# f29h85x_hsm_dcc0_regs register map
Vendor: Texas Instruments
Peripheral module from a debugger description file (folder HSM).
Registers are 32-bit, read-write, no defined reset value unless marked. A register's access mark holds for its fields unless they carry their own. Offsets are as the file gives them; lines under a group give offsets from that group; [hi:lo] are bit positions; {n}, {i} and the like mark numbered series; 'fields as' and 'values as' point back to an identical list; <NAME> marks a mode.

## HSM_DCC0 — HSM DCC0 Registers
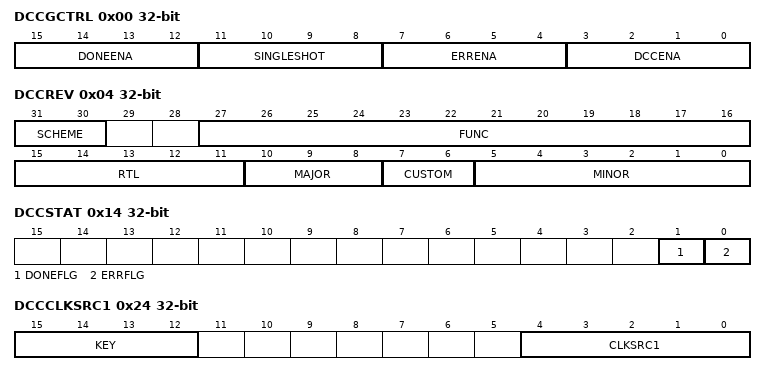
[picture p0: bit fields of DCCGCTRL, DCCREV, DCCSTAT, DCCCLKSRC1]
0x00 DCCGCTRL — DCC Global Control Register
  [15:12] DONEENA, [11:8] SINGLESHOT, [7:4] ERRENA, [3:0] DCCENA
0x04 DCCREV ro — DCC Revision ID
  [31:30] SCHEME, [27:16] FUNC, [15:11] RTL, [10:8] MAJOR, [7:6] CUSTOM, [5:0] MINOR
0x08 DCCCNTSEED0 — Count0 Seed Value Register
  [19:0] COUNTSEED0
0x0C DCCVALIDSEED0 — Valid0 Seed Value Register
  [15:0] VALIDSEED0
0x10 DCCCNTSEED1 — Count1 Seed Value Register
  [19:0] COUNTSEED1
0x14 DCCSTAT — DCC Status Register
  [1] DONEFLG, [0] ERRFLG
0x18 DCCCNT0 ro — Count0 Value Register
  [19:0] COUNT0
0x1C DCCVALID0 ro — Valid0 Value Register
  [15:0] VALID0
0x20 DCCCNT1 ro — Count1 Value Register
  [19:0] COUNT1
0x24 DCCCLKSRC1 — Clock Source Selection Register 1
  [15:12] KEY, [4:0] CLKSRC1
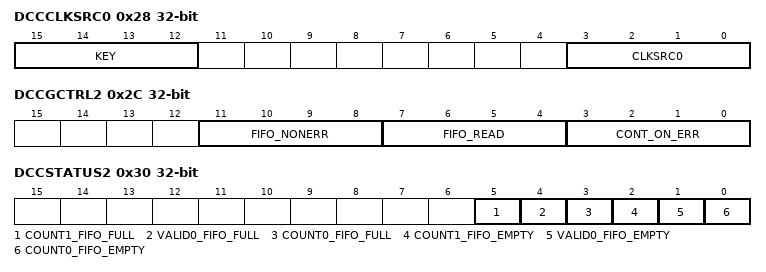
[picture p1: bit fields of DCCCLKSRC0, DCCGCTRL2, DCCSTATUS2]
0x28 DCCCLKSRC0 — Clock Source Selection Register 0
  [15:12] KEY, [3:0] CLKSRC0
0x2C DCCGCTRL2 — DCC Global Control Register 2
  [11:8] FIFO_NONERR, [7:4] FIFO_READ, [3:0] CONT_ON_ERR
0x30 DCCSTATUS2 ro — DCC FIFO Status Register
  [5] COUNT1_FIFO_FULL, [4] VALID0_FIFO_FULL, [3] COUNT0_FIFO_FULL, [2] COUNT1_FIFO_EMPTY, [1] VALID0_FIFO_EMPTY, [0] COUNT0_FIFO_EMPTY
0x34 DCCERRCNT — Error Count Register
  [9:0] ERRCNT
